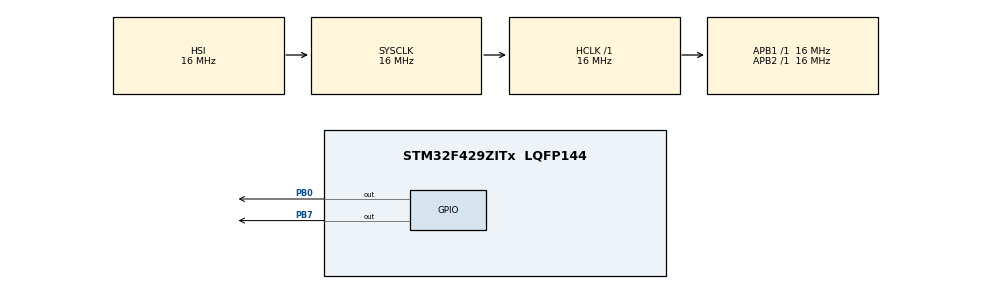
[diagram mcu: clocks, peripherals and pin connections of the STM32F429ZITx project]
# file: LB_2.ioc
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Mcu.Family=STM32F4
Mcu.Name=STM32F429ZITx
Mcu.Package=LQFP144
NVIC.PriorityGroup=NVIC_PRIORITYGROUP_4
NVIC.TIM1_BRK_TIM9_IRQn=true\:0\:0\:false\:false\:true\:true\:true\:true
NVIC.TIM1_UP_TIM10_IRQn=true\:0\:0\:false\:false\:true\:true\:true\:true
PA13.Mode=Serial_Wire
PA13.Signal=SYS_JTMS-SWDIO
PA14.Mode=Serial_Wire
PA14.Signal=SYS_JTCK-SWCLK
PB0.Signal=GPIO_Output
PB7.Signal=GPIO_Output
PH0/OSC_IN.Mode=HSE-External-Oscillator
PH0/OSC_IN.Signal=RCC_OSC_IN
PH1/OSC_OUT.Mode=HSE-External-Oscillator
PH1/OSC_OUT.Signal=RCC_OSC_OUT
ProjectManager.HeapSize=0x200
ProjectManager.StackSize=0x400
ProjectManager.TargetToolchain=STM32CubeIDE
RCC.AHBFreq_Value=16000000
RCC.APB1Freq_Value=16000000
RCC.APB2Freq_Value=16000000
RCC.CortexFreq_Value=16000000
RCC.HSE_VALUE=25000000
RCC.HSI_VALUE=16000000
RCC.LSE_VALUE=32768
RCC.SYSCLKFreq_VALUE=16000000
RCC.VCOOutputFreq_Value=192000000
TIM1.CounterMode=TIM_COUNTERMODE_DOWN
TIM1.Period=24000-1
TIM1.Prescaler=1000-1
TIM9.Period=5000-1
TIM9.Prescaler=1000-1
VP_TIM1_VS_ClockSourceINT.Mode=Internal
VP_TIM9_VS_ClockSourceINT.Mode=Internal
board=custom

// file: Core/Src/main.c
/* USER CODE BEGIN Header */
/**
  ******************************************************************************
  * @file           : main.c
  * @brief          : Main program body
  ******************************************************************************
  * @attention
  *
  * Copyright (c) 2023 STMicroelectronics.
  * All rights reserved.
  *
  * This software is licensed under terms that can be found in the LICENSE file
  * in the root directory of this software component.
  * If no LICENSE file comes with this software, it is provided AS-IS.
  *
  ******************************************************************************
  */
/* USER CODE END Header */
#include "main.h"
#include "tim.h"
#include "gpio.h"

/* USER CODE BEGIN PV */
uint32_t Tim1CNT;
uint8_t flag1;
uint32_t Tim9CNT;
uint8_t flag9;
/* USER CODE END PV */

void SystemClock_Config(void);

int main(void)
{

  /* MCU Configuration--------------------------------------------------------*/

  /* Reset of all peripherals, Initializes the Flash interface and the Systick. */
  HAL_Init();

  /* Configure the system clock */
  SystemClock_Config();

  /* Initialize all configured peripherals */
  MX_GPIO_Init();
  MX_TIM1_Init();
  MX_TIM9_Init();
  /* USER CODE BEGIN 2 */
HAL_TIM_Base_Start_IT(&htim1);
HAL_TIM_Base_Start_IT(&htim9);
  /* USER CODE END 2 */

  /* Infinite loop */
  /* USER CODE BEGIN WHILE */
  while (1)
  {
	  if(flag1) HAL_GPIO_WritePin(GPIOB, GPIO_PIN_7, SET);
	  else HAL_GPIO_WritePin(GPIOB, GPIO_PIN_7, RESET);
	  Tim1CNT = TIM1->CNT;
	  if(flag9) HAL_GPIO_WritePin(GPIOB, GPIO_PIN_0, SET);
	  else HAL_GPIO_WritePin(GPIOB, GPIO_PIN_0, RESET);
	  Tim9CNT = TIM9->CNT;
    /* USER CODE END WHILE */

  }
}

void SystemClock_Config(void)
{
  RCC_OscInitTypeDef RCC_OscInitStruct = {0};
  RCC_ClkInitTypeDef RCC_ClkInitStruct = {0};

  /** Configure the main internal regulator output voltage
  */
  __HAL_RCC_PWR_CLK_ENABLE();
  __HAL_PWR_VOLTAGESCALING_CONFIG(PWR_REGULATOR_VOLTAGE_SCALE3);

  /** Initializes the RCC Oscillators according to the specified parameters
  * in the RCC_OscInitTypeDef structure.
  */
  RCC_OscInitStruct.OscillatorType = RCC_OSCILLATORTYPE_HSI;
  RCC_OscInitStruct.HSIState = RCC_HSI_ON;
  RCC_OscInitStruct.HSICalibrationValue = RCC_HSICALIBRATION_DEFAULT;
  RCC_OscInitStruct.PLL.PLLState = RCC_PLL_NONE;
  if (HAL_RCC_OscConfig(&RCC_OscInitStruct) != HAL_OK)
  {
    Error_Handler();
  }

  /** Initializes the CPU, AHB and APB buses clocks
  */
  RCC_ClkInitStruct.ClockType = RCC_CLOCKTYPE_HCLK|RCC_CLOCKTYPE_SYSCLK
                              |RCC_CLOCKTYPE_PCLK1|RCC_CLOCKTYPE_PCLK2;
  RCC_ClkInitStruct.SYSCLKSource = RCC_SYSCLKSOURCE_HSI;
  RCC_ClkInitStruct.AHBCLKDivider = RCC_SYSCLK_DIV1;
  RCC_ClkInitStruct.APB1CLKDivider = RCC_HCLK_DIV1;
  RCC_ClkInitStruct.APB2CLKDivider = RCC_HCLK_DIV1;

  if (HAL_RCC_ClockConfig(&RCC_ClkInitStruct, FLASH_LATENCY_0) != HAL_OK)
  {
    Error_Handler();
  }
}

void Error_Handler(void)
{
  __disable_irq();
  while (1)
  {
  }
}
